/****************************************************************************
** File : LIN_LDF.ldf
** Description : LIN Description file for the defined LIN cluster
*****************************************************************************/

LIN_description_file;
LIN_Protocol_Version = "2.1";
LIN_language_version = "2.1";
LIN_speed = 19.2 kbps;
Channel_name = "LIN_Configuration1";

Nodes {
    Master: ledController, 5 ms, .1 ms;
    Slaves: pcClient;
}

Signals {
    HMI_status_light_control
: 1,0,pcClient,ledController;
    HMI_status_lightness: 2,0,pcClient,ledController;
    HMI_status_light_mode: 8,0,pcClient,ledController;
    FreeMode_LightMatrix_L: 4,0,pcClient,ledController;
    FreeMode_LightMatrix_T: 4,0,pcClient,ledController;
    FreeMode_LightMatrix_R: 4,0,pcClient,ledController;
    HMI_status_light_status: 2,0,ledController,pcClient;
    HMI_status_lightness_report: 2,0,ledController,pcClient;
    HMI_status_light_mode_report: 8,0,ledController,pcClient;
}

Frames {
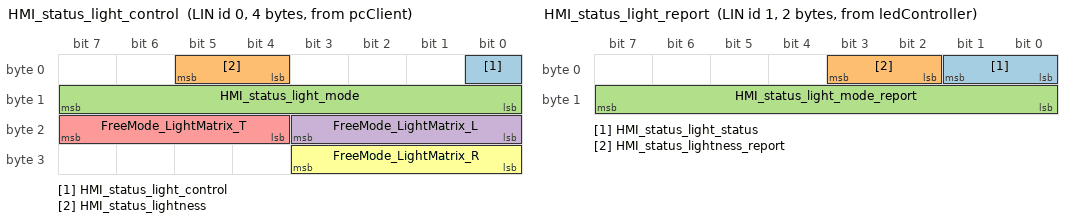
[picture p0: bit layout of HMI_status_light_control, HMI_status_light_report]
    HMI_status_light_control:0,pcClient,4{
        HMI_status_light_control
,0;
        HMI_status_lightness,4;
        HMI_status_light_mode,8;
        FreeMode_LightMatrix_L,16;
        FreeMode_LightMatrix_T,20;
        FreeMode_LightMatrix_R,24;
    }
    HMI_status_light_report:1,ledController,2{
        HMI_status_light_status,0;
        HMI_status_lightness_report,2;
        HMI_status_light_mode_report,8;
    }
}

Sporadic_frames {
}

Event_triggered_frames {
}

Node_attributes {
    pcClient {
        LIN_protocol = 2.1;
        configured_NAD = 2;
        initial_NAD = 2;
        product_id = 0,0,0;
        /*Resonse error signal: not configured in GUI*/
        /*fault_state_signals: not configured in GUI*/
        P2_min = 50 ms;
        ST_min = 0 ms;
        N_As_timeout = 1000 ms;
        N_Cr_timeout = 1000 ms;
        configurable_frames {
                 HMI_status_light_control;
                 HMI_status_light_report;
        }
    }
}

Schedule_tables {
    Schedule100ms {
        MasterReq delay 100 ms;
        SlaveResp delay 100 ms;
        HMI_status_light_control delay 100 ms;
        HMI_status_light_report delay 100 ms;
    }
}
